AUTOSAR XML (schema 4-3-0)
package /MICROSAR/BswM_swc
  data type mapping set BswMMappingSet: mode-request-type-map{implementation-data-type=Dcm_EcuResetType, mode-group=DcmEcuReset}  # Contains Mapping for ModeDeclarations Groups which are provided by BswM.
package /MICROSAR/BswM_swc/ComponentTypes
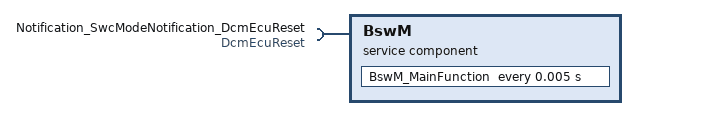
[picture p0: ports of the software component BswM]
  service sw component type BswM: category=SERVICE_COMPONENT
    require port Notification_SwcModeNotification_DcmEcuReset: required-interface=DcmEcuReset
    behavior BswMInternalBehavior: data-type-mapping=BswMMappingSet, handle-termination-and-restart=NO-SUPPORT, port-api-option{enable-take-address=true, indirect-api=false, port=Notification_SwcModeNotification_DcmEcuReset}
      timing event Timer_BswM_MainFunction: start-on-event=BswM_MainFunction, period=0.005
      runnable BswM_MainFunction: mode-access-point=Notification_SwcModeNotification_DcmEcuReset.DcmEcuReset
  swc implementation BswMImplementation: programming-language=C, behavior=BswMInternalBehavior
